VERSION ""

NS_ :

BS_:

BU_: AEMNet_UEGO AEMNet_EGT ECU

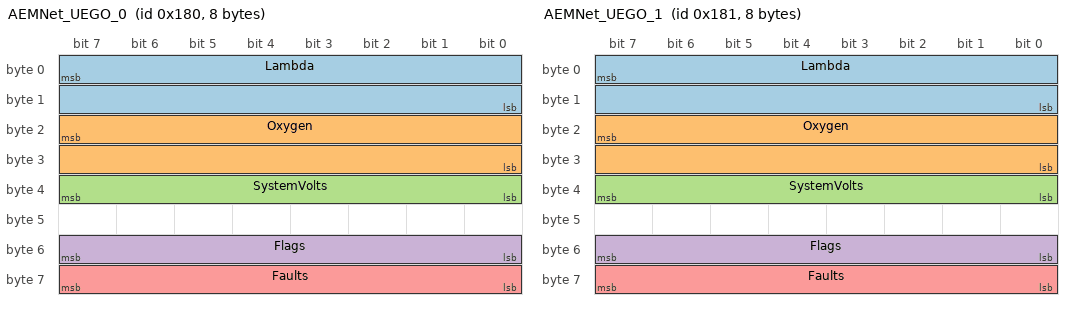
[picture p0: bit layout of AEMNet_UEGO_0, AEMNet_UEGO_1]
BO_ 384 AEMNet_UEGO_0: 8 AEMNet_UEGO
 SG_ Lambda : 7|16@0+ (0.0001,0) [0|6.5535] "lambda"  ECU
 SG_ Oxygen : 23|16@0- (0.001,0) [-32.768|32.768] "%"  ECU
 SG_ SystemVolts : 39|8@0+ (0.1,0) [0|25.5] "V"  ECU
 SG_ Flags : 55|8@0+ (1,0) [0|255] ""  ECU
 SG_ Faults : 63|8@0+ (1,0) [0|255] ""  ECU

BO_ 385 AEMNet_UEGO_1: 8 AEMNet_UEGO
 SG_ Lambda : 7|16@0+ (0.0001,0) [0|6.5535] "lambda"  ECU
 SG_ Oxygen : 23|16@0- (0.001,0) [-32.768|32.768] "%"  ECU
 SG_ SystemVolts : 39|8@0+ (0.1,0) [0|25.5] "V"  ECU
 SG_ Flags : 55|8@0+ (1,0) [0|255] ""  ECU
 SG_ Faults : 63|8@0+ (1,0) [0|255] ""  ECU

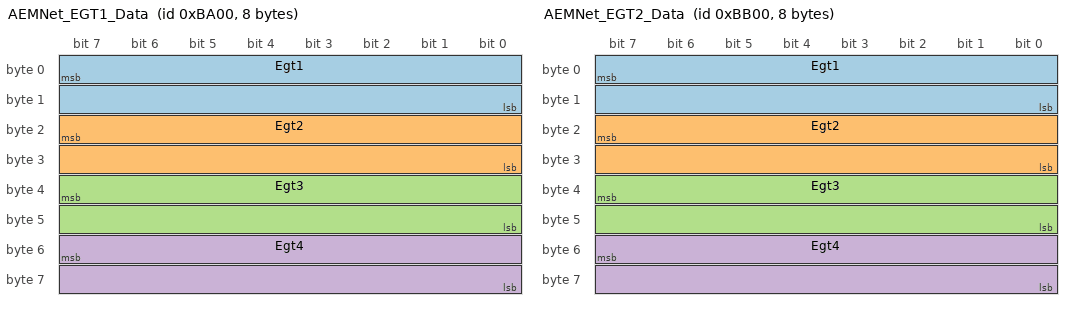
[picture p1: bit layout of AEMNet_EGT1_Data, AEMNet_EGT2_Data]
BO_ 47616 AEMNet_EGT1_Data: 8 AEMNet_EGT
 SG_ Egt1 : 7|16@0- (0.1,0) [-3276.8|3276.7] "degC"  ECU
 SG_ Egt2 : 23|16@0- (0.1,0) [-3276.8|3276.7] "degC"  ECU
 SG_ Egt3 : 39|16@0- (0.1,0) [-3276.8|3276.7] "degC"  ECU
 SG_ Egt4 : 55|16@0- (0.1,0) [-3276.8|3276.7] "degC"  ECU

BO_ 47617 AEMNet_EGT1_Status: 8 AEMNet_EGT
 SG_ ColdJunctionTemp : 7|16@0- (0.1,0) [-3276.8|3276.7] "degC"  ECU
 SG_ BatteryVoltage : 23|8@0+ (0.1,0) [0|25.5] "V"  ECU

BO_ 47872 AEMNet_EGT2_Data: 8 AEMNet_EGT
 SG_ Egt1 : 7|16@0- (0.1,0) [-3276.8|3276.7] "degC"  ECU
 SG_ Egt2 : 23|16@0- (0.1,0) [-3276.8|3276.7] "degC"  ECU
 SG_ Egt3 : 39|16@0- (0.1,0) [-3276.8|3276.7] "degC"  ECU
 SG_ Egt4 : 55|16@0- (0.1,0) [-3276.8|3276.7] "degC"  ECU

BO_ 47873 AEMNet_EGT2_Status: 8 AEMNet_EGT
 SG_ ColdJunctionTemp : 7|16@0- (0.1,0) [-3276.8|3276.7] "degC"  ECU
 SG_ BatteryVoltage : 23|8@0+ (0.1,0) [0|25.5] "V"  ECU

CM_ BO_ 384 "AEMNet UEGO";
CM_ SG_ 384 Flags "Bit[1]=LSU4.9 detected, Bit[5]=Free-Air cal in use, Bit[7]=Lambda data valid";
CM_ SG_ 384 Faults "Bit[6]=Sensor Fault";

CM_ BO_ 47616 "AEMNet EGT Data for unit 1";
CM_ BO_ 47617 "AEMNet EGT Status for unit 1";
CM_ BO_ 47872 "AEMNet EGT Data for unit 2";
CM_ BO_ 47873 "AEMNet EGT Status for unit 2";

BA_DEF_ "BusType" STRING ;
BA_DEF_DEF_ "BusType" "CAN";
